# CH564 register map
Vendor: WCH Ltd.; File version: 1.0
Registers are 8-bit, read-write, reset 0x0 unless marked. A register's access mark holds for its fields unless they carry their own. Offsets are from the block's base; [hi:lo] are bit positions.

## ETHERNET_MAC — Ethernet: media access control
Base 0x40028000
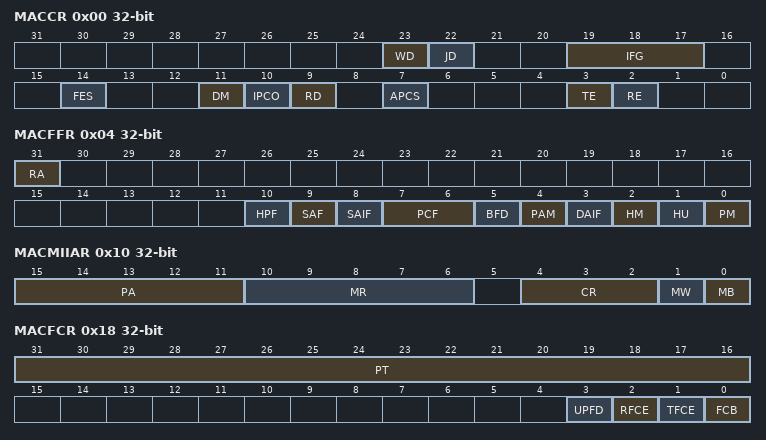
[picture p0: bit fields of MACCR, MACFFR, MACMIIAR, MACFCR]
0x00 MACCR 32-bit — Ethernet MAC configuration register (ETH_MACCR)
  [23] WD — Watchdog disable
  [22] JD — Jabber disable
  [19:17] IFG — Interframe gap
  [14] FES — Fast Ethernet speed
  [11] DM — Duplex mode
  [10] IPCO — IPv4 checksum offload
  [9] RD — Retry disable
  [7] APCS — Automatic pad/CRC stripping
  [3] TE — Transmitter enable
  [2] RE — Receiver enable
0x04 MACFFR 32-bit — Ethernet MAC frame filter register (ETH_MACCFFR)
  [31] RA — Receive all
  [10] HPF — Hash or perfect filter
  [9] SAF — Source address filter
  [8] SAIF — Source address inverse filtering
  [7:6] PCF — Pass control frames
  [5] BFD — Broadcast frames disable
  [4] PAM — Pass all multicast
  [3] DAIF — Destination address inverse filtering
  [2] HM — Hash multicast
  [1] HU — Hash unicast
  [0] PM — Promiscuous mode
0x08 MACHTHR 32-bit — Ethernet MAC hash table high register
  [31:0] HTH — Hash table high
0x0C MACHTLR 32-bit — Ethernet MAC hash table low register
  [31:0] HTL — Hash table low
0x10 MACMIIAR 32-bit — Ethernet MAC MII address register (ETH_MACMIIAR)
  [15:11] PA — PHY address
  [10:6] MR — MII register
  [4:2] CR — Clock range
  [1] MW — MII write
  [0] MB — MII busy
0x14 MACMIIDR 32-bit — Ethernet MAC MII data register (ETH_MACMIIDR)
  [15:0] MD — MII data
0x18 MACFCR 32-bit — Ethernet MAC flow control register (ETH_MACFCR)
  [31:16] PT — Pass control frames
  [3] UPFD — Unicast pause frame detect
  [2] RFCE — Receive flow control enable
  [1] TFCE — Transmit flow control enable
  [0] FCB — Flow control busy
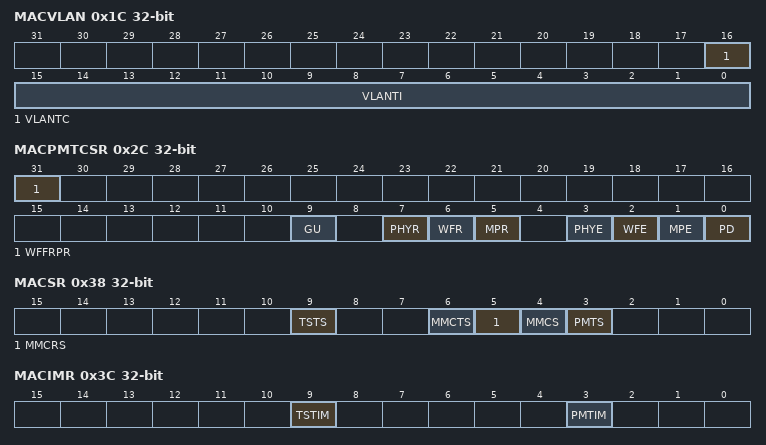
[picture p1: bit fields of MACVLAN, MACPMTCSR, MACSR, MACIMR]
0x1C MACVLAN 32-bit — Ethernet MAC VLAN tag register (ETH_MACVLAN)
  [16] VLANTC — 12-bit VLAN tag comparison
  [15:0] VLANTI — VLAN tag identifier (for receive frames)
0x28 MACRWUFFR 32-bit — Ethernet MAC remote wakeup frame filter register (ETH_MACRWUFFR)
0x2C MACPMTCSR 32-bit — Ethernet MAC PMT control and status register (ETH_MACPMTCSR)
  [31] WFFRPR — Wakeup frame filter register pointer reset
  [9] GU — Global unicast
  [7] PHYR — wake-up frame flag bit of PHY
  [6] WFR — Wakeup frame received
  [5] MPR — Magic packet received
  [3] PHYE — PMEB of PHY enable
  [2] WFE — Wakeup frame enable
  [1] MPE — Magic Packet enable
  [0] PD — Power down
0x38 MACSR 32-bit — Ethernet MAC interrupt status register (ETH_MACSR)
  [9] TSTS — Time stamp trigger status
  [6] MMCTS — MMC transmit status
  [5] MMCRS — MMC receive status
  [4] MMCS — MMC status
  [3] PMTS — PMT status
0x3C MACIMR 32-bit — Ethernet MAC interrupt mask register (ETH_MACIMR)
  [9] TSTIM — Time stamp trigger interrupt mask
  [3] PMTIM — PMT interrupt mask
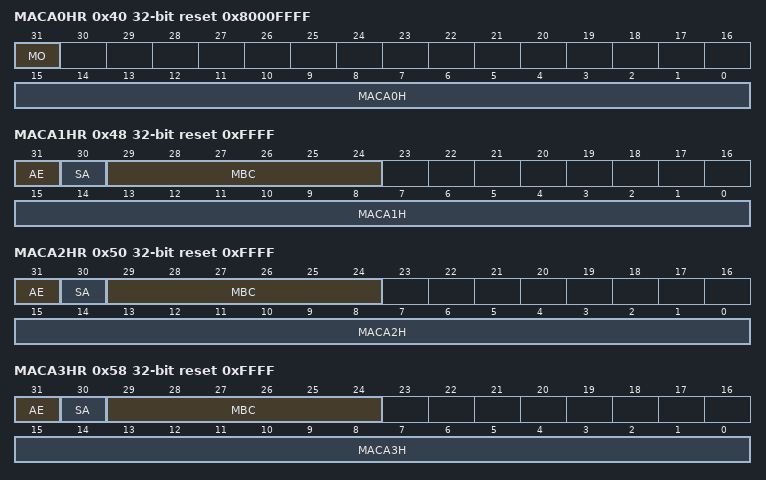
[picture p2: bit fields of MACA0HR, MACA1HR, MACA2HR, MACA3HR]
0x40 MACA0HR 32-bit access per field reset 0x8000FFFF — Ethernet MAC address 0 high register (ETH_MACA0HR)
  [31] MO ro — Always 1
  [15:0] MACA0H rw — MAC address0 high
0x44 MACA0LR 32-bit reset 0xFFFFFFFF — Ethernet MAC address 0 low register
  [31:0] MACA0L — MAC address0 low
0x48 MACA1HR 32-bit reset 0xFFFF — Ethernet MAC address 1 high register (ETH_MACA1HR)
  [31] AE — Address enable
  [30] SA — Source address
  [29:24] MBC — Mask byte control
  [15:0] MACA1H — MAC address1 high
0x4C MACA1LR 32-bit reset 0xFFFFFFFF — Ethernet MAC address1 low register
  [31:0] MACA1L — MAC address1 low
0x50 MACA2HR 32-bit reset 0xFFFF — Ethernet MAC address 2 high register (ETH_MACA2HR)
  [31] AE — Address enable
  [30] SA — Source address
  [29:24] MBC — Mask byte control
  [15:0] MACA2H — Ethernet MAC address 2 high register
0x54 MACA2LR 32-bit reset 0xFFFFFFFF — Ethernet MAC address 2 low register
  [30:0] MACA2L — MAC address2 low
0x58 MACA3HR 32-bit reset 0xFFFF — Ethernet MAC address 3 high register (ETH_MACA3HR)
  [31] AE — Address enable
  [30] SA — Source address
  [29:24] MBC — Mask byte control
  [15:0] MACA3H — MAC address3 high
0x5C MACA3LR 32-bit reset 0xFFFFFFFF — Ethernet MAC address 3 low register
  [31:0] MBCA3L — MAC address3 low
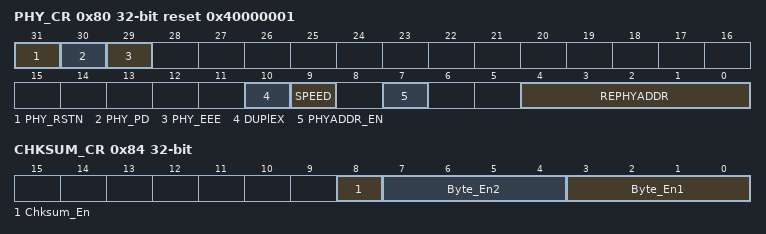
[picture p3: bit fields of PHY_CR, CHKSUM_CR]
0x80 PHY_CR 32-bit access per field reset 0x40000001 — PHY configure register
  [31] PHY_RSTN rw — Ethernet PHY global reset signal
  [30] PHY_PD rw — PHY pd mode selection
  [29] PHY_EEE rw — PHY work mode selection
  [10] DUPlEX ro — Even Ethernet mode selection
  [9] SPEED ro — Even Ethernet speed selection
  [7] PHYADDR_EN rw — Reconfigure the PHY address
  [4:0] REPHYADDR rw — when the bit 7 set 1,bit4-0 serves as the address of the PHY
0x84 CHKSUM_CR 32-bit — CHKSUM configure register
  [8] Chksum_En — the software sets 1 at the beginning of frame calculation and write 0 at the end of frame calculation
  [7:4] Byte_En2 — Participate in the ip header checksum to calculate byte control bits
  [3:0] Byte_En1 — Participate in the ip header checksum to calculate byte control bits
0x88 IP_PDR 32-bit — IP packet register
  [31:0] IP_Payload — IP data written by software,need to be used with ETH_CHKSUM_CR
0x8C CHKSUM_HR 32-bit — IP packet register
  [15:0] Chksum_Head_Result — IP header checksum
0x90 CHKSUM_PR 32-bit — IP data register
  [15:0] Chksum_Head_Result — IP header checksum
